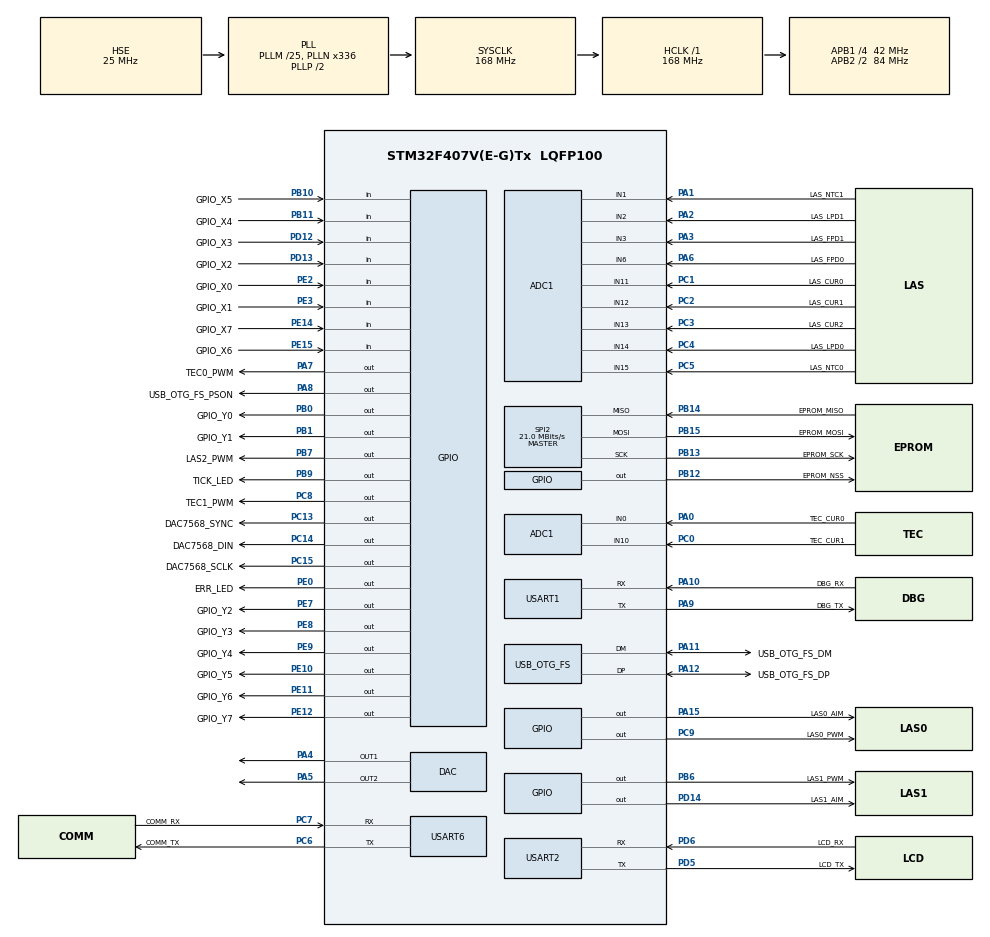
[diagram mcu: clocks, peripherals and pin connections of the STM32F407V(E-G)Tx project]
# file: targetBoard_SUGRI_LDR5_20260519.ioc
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ADC1.Channel-0\#ChannelRegularConversion=ADC_CHANNEL_0
ADC1.Channel-1\#ChannelRegularConversion=ADC_CHANNEL_1
ADC1.Channel-10\#ChannelRegularConversion=ADC_CHANNEL_15
ADC1.Channel-11\#ChannelRegularConversion=ADC_CHANNEL_TEMPSENSOR
ADC1.Channel-12\#ChannelRegularConversion=ADC_CHANNEL_VREFINT
ADC1.Channel-13\#ChannelRegularConversion=ADC_CHANNEL_VBAT
ADC1.Channel-2\#ChannelRegularConversion=ADC_CHANNEL_2
ADC1.Channel-3\#ChannelRegularConversion=ADC_CHANNEL_3
ADC1.Channel-4\#ChannelRegularConversion=ADC_CHANNEL_6
ADC1.Channel-5\#ChannelRegularConversion=ADC_CHANNEL_10
ADC1.Channel-6\#ChannelRegularConversion=ADC_CHANNEL_11
ADC1.Channel-7\#ChannelRegularConversion=ADC_CHANNEL_12
ADC1.Channel-8\#ChannelRegularConversion=ADC_CHANNEL_13
ADC1.Channel-9\#ChannelRegularConversion=ADC_CHANNEL_14
ADC1.ContinuousConvMode=ENABLE
ADC1.DMAContinuousRequests=DISABLE
ADC1.NbrOfConversion=14
ADC1.NbrOfConversionFlag=1
ADC1.Rank-0\#ChannelRegularConversion=1
ADC1.Rank-1\#ChannelRegularConversion=2
ADC1.Rank-10\#ChannelRegularConversion=11
ADC1.Rank-11\#ChannelRegularConversion=12
ADC1.Rank-12\#ChannelRegularConversion=13
ADC1.Rank-13\#ChannelRegularConversion=14
ADC1.Rank-2\#ChannelRegularConversion=3
ADC1.Rank-3\#ChannelRegularConversion=4
ADC1.Rank-4\#ChannelRegularConversion=5
ADC1.Rank-5\#ChannelRegularConversion=6
ADC1.Rank-6\#ChannelRegularConversion=7
ADC1.Rank-7\#ChannelRegularConversion=8
ADC1.Rank-8\#ChannelRegularConversion=9
ADC1.Rank-9\#ChannelRegularConversion=10
ADC1.SamplingTime-0\#ChannelRegularConversion=ADC_SAMPLETIME_144CYCLES
ADC1.SamplingTime-1\#ChannelRegularConversion=ADC_SAMPLETIME_144CYCLES
ADC1.SamplingTime-10\#ChannelRegularConversion=ADC_SAMPLETIME_144CYCLES
ADC1.SamplingTime-11\#ChannelRegularConversion=ADC_SAMPLETIME_144CYCLES
ADC1.SamplingTime-12\#ChannelRegularConversion=ADC_SAMPLETIME_144CYCLES
ADC1.SamplingTime-13\#ChannelRegularConversion=ADC_SAMPLETIME_144CYCLES
ADC1.SamplingTime-2\#ChannelRegularConversion=ADC_SAMPLETIME_144CYCLES
ADC1.SamplingTime-3\#ChannelRegularConversion=ADC_SAMPLETIME_144CYCLES
ADC1.SamplingTime-4\#ChannelRegularConversion=ADC_SAMPLETIME_144CYCLES
ADC1.SamplingTime-5\#ChannelRegularConversion=ADC_SAMPLETIME_144CYCLES
ADC1.SamplingTime-6\#ChannelRegularConversion=ADC_SAMPLETIME_144CYCLES
ADC1.SamplingTime-7\#ChannelRegularConversion=ADC_SAMPLETIME_144CYCLES
ADC1.SamplingTime-8\#ChannelRegularConversion=ADC_SAMPLETIME_144CYCLES
ADC1.SamplingTime-9\#ChannelRegularConversion=ADC_SAMPLETIME_144CYCLES
ADC1.ScanConvMode=ENABLE
ADC1.master=1
FATFS._CODE_PAGE=437
FATFS._FS_EXFAT=1
FATFS._FS_LOCK=255
FATFS._STRF_ENCODE=0
FATFS._USE_CHMOD=0
FATFS._USE_EXPAND=0
FATFS._USE_FASTSEEK=0
FATFS._USE_FIND=0
FATFS._USE_FORWARD=0
FATFS._USE_LABEL=0
FATFS._USE_LFN=3
FATFS._USE_MKFS=0
FATFS._USE_MUTEX=1
FATFS._USE_STRFUNC=0
Mcu.Family=STM32F4
Mcu.Name=STM32F407V(E-G)Tx
Mcu.Package=LQFP100
NVIC.OTG_FS_IRQn=true\:0\:0\:false\:false\:true\:false\:true\:true
NVIC.PriorityGroup=NVIC_PRIORITYGROUP_4
NVIC.TIM6_DAC_IRQn=true\:15\:0\:false\:false\:true\:false\:true\:true
NVIC.TimeBase=TIM6_DAC_IRQn
NVIC.TimeBaseIP=TIM6
PA0-WKUP.GPIO_Label=TEC_CUR0
PA0-WKUP.Signal=ADCx_IN0
PA1.GPIO_Label=LAS_NTC1
PA1.Signal=ADCx_IN1
PA10.GPIO_Label=DBG_RX
PA10.GPIO_PuPd=GPIO_PULLDOWN
PA10.GPIO_Speed=GPIO_SPEED_FREQ_MEDIUM
PA10.Mode=Asynchronous
PA10.Signal=USART1_RX
PA11.GPIO_Label=USB_OTG_FS_DM
PA11.Mode=Host_Only
PA11.Signal=USB_OTG_FS_DM
PA12.GPIO_Label=USB_OTG_FS_DP
PA12.Mode=Host_Only
PA12.Signal=USB_OTG_FS_DP
PA13.Mode=Trace_Asynchronous_SW
PA13.Signal=SYS_JTMS-SWDIO
PA14.Mode=Trace_Asynchronous_SW
PA14.Signal=SYS_JTCK-SWCLK
PA15.GPIO_Label=LAS0_AIM
PA15.GPIO_PuPd=GPIO_PULLDOWN
PA15.Signal=GPIO_Output
PA2.GPIO_Label=LAS_LPD1
PA2.Signal=ADCx_IN2
PA3.GPIO_Label=LAS_FPD1
PA3.Signal=ADCx_IN3
PA4.Signal=COMP_DAC1_group
PA5.Signal=COMP_DAC2_group
PA6.GPIO_Label=LAS_FPD0
PA6.Signal=ADCx_IN6
PA7.GPIO_Label=TEC0_PWM
PA7.GPIO_ModeDefaultOutputPP=GPIO_MODE_OUTPUT_PP
PA7.GPIO_PuPd=GPIO_PULLDOWN
PA7.Signal=GPIO_Output
PA8.GPIO_Label=USB_OTG_FS_PSON
PA8.GPIO_ModeDefaultOutputPP=GPIO_MODE_OUTPUT_PP
PA8.GPIO_PuPd=GPIO_PULLDOWN
PA8.Signal=GPIO_Output
PA9.GPIO_Label=DBG_TX
PA9.GPIO_PuPd=GPIO_PULLDOWN
PA9.GPIO_Speed=GPIO_SPEED_FREQ_MEDIUM
PA9.Mode=Asynchronous
PA9.Signal=USART1_TX
PB0.GPIO_Label=GPIO_Y0
PB0.GPIO_PuPd=GPIO_PULLDOWN
PB0.Signal=GPIO_Output
PB1.GPIO_Label=GPIO_Y1
PB1.GPIO_PuPd=GPIO_PULLDOWN
PB1.Signal=GPIO_Output
PB10.GPIO_Label=GPIO_X5
PB10.GPIO_PuPd=GPIO_PULLUP
PB10.Signal=GPIO_Input
PB11.GPIO_Label=GPIO_X4
PB11.GPIO_PuPd=GPIO_PULLUP
PB11.Signal=GPIO_Input
PB12.GPIO_Label=EPROM_NSS
PB12.Signal=GPIO_Output
PB13.GPIO_Label=EPROM_SCK
PB13.GPIO_PuPd=GPIO_PULLUP
PB13.Mode=Full_Duplex_Master
PB13.Signal=SPI2_SCK
PB14.GPIO_Label=EPROM_MISO
PB14.GPIO_PuPd=GPIO_PULLDOWN
PB14.Mode=Full_Duplex_Master
PB14.Signal=SPI2_MISO
PB15.GPIO_Label=EPROM_MOSI
PB15.GPIO_PuPd=GPIO_PULLDOWN
PB15.Mode=Full_Duplex_Master
PB15.Signal=SPI2_MOSI
PB3.Mode=Trace_Asynchronous_SW
PB3.Signal=SYS_JTDO-SWO
PB6.GPIO_Label=LAS1_PWM
PB6.GPIO_PuPd=GPIO_PULLDOWN
PB6.Signal=GPIO_Output
PB7.GPIO_Label=LAS2_PWM
PB7.GPIO_PuPd=GPIO_PULLDOWN
PB7.Signal=GPIO_Output
PB9.GPIO_Label=TICK_LED
PB9.Signal=GPIO_Output
PC0.GPIO_Label=TEC_CUR1
PC0.Signal=ADCx_IN10
PC1.GPIO_Label=LAS_CUR0
PC1.Signal=ADCx_IN11
PC13-ANTI_TAMP.GPIO_Label=DAC7568_SYNC
PC13-ANTI_TAMP.GPIO_PuPd=GPIO_PULLUP
PC13-ANTI_TAMP.Signal=GPIO_Output
PC14-OSC32_IN.GPIO_Label=DAC7568_DIN
PC14-OSC32_IN.Signal=GPIO_Output
PC15-OSC32_OUT.GPIO_Label=DAC7568_SCLK
PC15-OSC32_OUT.Signal=GPIO_Output
PC2.GPIO_Label=LAS_CUR1
PC2.Signal=ADCx_IN12
PC3.GPIO_Label=LAS_CUR2
PC3.Signal=ADCx_IN13
PC4.GPIO_Label=LAS_LPD0
PC4.Signal=ADCx_IN14
PC5.GPIO_Label=LAS_NTC0
PC5.Signal=ADCx_IN15
PC6.GPIO_Label=COMM_TX
PC6.Mode=Asynchronous
PC6.Signal=USART6_TX
PC7.GPIO_Label=COMM_RX
PC7.Mode=Asynchronous
PC7.Signal=USART6_RX
PC8.GPIO_Label=TEC1_PWM
PC8.GPIO_PuPd=GPIO_PULLDOWN
PC8.Signal=GPIO_Output
PC9.GPIO_Label=LAS0_PWM
PC9.GPIO_PuPd=GPIO_PULLDOWN
PC9.Signal=GPIO_Output
PD12.GPIO_Label=GPIO_X3
PD12.GPIO_PuPd=GPIO_PULLUP
PD12.Signal=GPIO_Input
PD13.GPIO_Label=GPIO_X2
PD13.GPIO_PuPd=GPIO_PULLUP
PD13.Signal=GPIO_Input
PD14.GPIO_Label=LAS1_AIM
PD14.GPIO_PuPd=GPIO_PULLDOWN
PD14.Signal=GPIO_Output
PD5.GPIO_Label=LCD_TX
PD5.Mode=Asynchronous
PD5.Signal=USART2_TX
PD6.GPIO_Label=LCD_RX
PD6.Mode=Asynchronous
PD6.Signal=USART2_RX
PE0.GPIO_Label=ERR_LED
PE0.GPIO_PuPd=GPIO_NOPULL
PE0.Signal=GPIO_Output
PE10.GPIO_Label=GPIO_Y5
PE10.GPIO_PuPd=GPIO_PULLDOWN
PE10.Signal=GPIO_Output
PE11.GPIO_Label=GPIO_Y6
PE11.GPIO_PuPd=GPIO_PULLDOWN
PE11.Signal=GPIO_Output
PE12.GPIO_Label=GPIO_Y7
PE12.GPIO_PuPd=GPIO_PULLDOWN
PE12.Signal=GPIO_Output
PE14.GPIO_Label=GPIO_X7
PE14.GPIO_PuPd=GPIO_PULLUP
PE14.Signal=GPIO_Input
PE15.GPIO_Label=GPIO_X6
PE15.GPIO_PuPd=GPIO_PULLUP
PE15.Signal=GPIO_Input
PE2.GPIO_Label=GPIO_X0
PE2.GPIO_PuPd=GPIO_PULLUP
PE2.Signal=GPIO_Input
PE3.GPIO_Label=GPIO_X1
PE3.GPIO_PuPd=GPIO_PULLUP
PE3.Signal=GPIO_Input
PE7.GPIO_Label=GPIO_Y2
PE7.GPIO_PuPd=GPIO_PULLDOWN
PE7.Signal=GPIO_Output
PE8.GPIO_Label=GPIO_Y3
PE8.GPIO_PuPd=GPIO_PULLDOWN
PE8.Signal=GPIO_Output
PE9.GPIO_Label=GPIO_Y4
PE9.GPIO_PuPd=GPIO_PULLDOWN
PE9.Signal=GPIO_Output
PH0-OSC_IN.Mode=HSE-External-Oscillator
PH0-OSC_IN.Signal=RCC_OSC_IN
PH1-OSC_OUT.Mode=HSE-External-Oscillator
PH1-OSC_OUT.Signal=RCC_OSC_OUT
ProjectManager.HeapSize=0x2000
ProjectManager.StackSize=0x1000
ProjectManager.TargetToolchain=MDK-ARM V5.32
RCC.48MHZClocksFreq_Value=48000000
RCC.AHBFreq_Value=168000000
RCC.APB1CLKDivider=RCC_HCLK_DIV4
RCC.APB1Freq_Value=42000000
RCC.APB1TimFreq_Value=84000000
RCC.APB2CLKDivider=RCC_HCLK_DIV2
RCC.APB2Freq_Value=84000000
RCC.APB2TimFreq_Value=168000000
RCC.CortexFreq_Value=168000000
RCC.HCLKFreq_Value=168000000
RCC.HSE_VALUE=25000000
RCC.HSI_VALUE=16000000
RCC.LSE_VALUE=32768
RCC.PLLM=25
RCC.PLLN=336
RCC.PLLQ=7
RCC.PWR_Regulator_Voltage_Scale=PWR_REGULATOR_VOLTAGE_SCALE1
RCC.RCC_RTC_Clock_Source=RCC_RTCCLKSOURCE_LSE
RCC.RCC_RTC_Clock_SourceVirtual=RCC_RTCCLKSOURCE_LSE
RCC.SYSCLKFreq_VALUE=168000000
RCC.SYSCLKSource=RCC_SYSCLKSOURCE_PLLCLK
RCC.VCOOutputFreq_Value=336000000
SH.ADCx_IN0.0=ADC1_IN0,IN0
SH.ADCx_IN1.0=ADC1_IN1,IN1
SH.ADCx_IN10.0=ADC1_IN10,IN10
SH.ADCx_IN11.0=ADC1_IN11,IN11
SH.ADCx_IN12.0=ADC1_IN12,IN12
SH.ADCx_IN13.0=ADC1_IN13,IN13
SH.ADCx_IN14.0=ADC1_IN14,IN14
SH.ADCx_IN15.0=ADC1_IN15,IN15
SH.ADCx_IN2.0=ADC1_IN2,IN2
SH.ADCx_IN3.0=ADC1_IN3,IN3
SH.ADCx_IN6.0=ADC1_IN6,IN6
SH.COMP_DAC1_group.0=DAC_OUT1,DAC_OUT1
SH.COMP_DAC2_group.0=DAC_OUT2,DAC_OUT2
SPI2.CalculateBaudRate=21.0 MBits/s
SPI2.Direction=SPI_DIRECTION_2LINES
SPI2.Mode=SPI_MODE_MASTER
SPI2.VirtualType=VM_MASTER
USART1.VirtualMode=VM_ASYNC
USART2.VirtualMode=VM_ASYNC
USART6.VirtualMode=VM_ASYNC
USB_HOST.BSP.number=1
USB_HOST.USBH_DEBUG_LEVEL-MSC_FS=0
USB_HOST.USBH_HandleTypeDef-MSC_FS=hUsbHostFS
USB_HOST.VirtualModeFS=Msc
USB_HOST0.BSP.STBoard=false
USB_HOST0.BSP.api=Unknown
USB_HOST0.BSP.condition=SW_VBUS_DRIVE_MSC_FS \= false
USB_HOST0.BSP.instance=PA8
USB_HOST0.BSP.ip=GPIO
USB_HOST0.BSP.mode=Output
USB_HOST0.BSP.name=Drive_VBUS_FS
USB_HOST0.BSP.solution=PA8
USB_OTG_FS.VirtualMode=Host_Only
USB_OTG_FS.phy_itface=HCD_PHY_EMBEDDED
VP_ADC1_TempSens_Input.Mode=IN-TempSens
VP_ADC1_Vbat_Input.Mode=IN-Vbat
VP_ADC1_Vref_Input.Mode=IN-Vrefint
VP_CRC_VS_CRC.Mode=CRC_Activate
VP_FATFS_VS_USB.Mode=USB
VP_RNG_VS_RNG.Mode=RNG_Activate
VP_SYS_VS_tim6.Mode=TIM6
VP_USB_HOST_VS_USB_HOST_MSC_FS.Mode=MSC_FS
board=custom

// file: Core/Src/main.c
/*----------------------------------------------------------------------------
 * 文件编码约定: 本文件为 UTF-8 编码(带BOM)。
 * 本工程源码统一使用 UTF-8(带BOM) 保存: 新建或修改任何源文件时,
 * 请以 UTF-8 编码保存, 并在文件头保留本注释。
 *----------------------------------------------------------------------------*/
/* USER CODE BEGIN Header */
/**
  ******************************************************************************
  * @file           : main.c
  * @brief          : Main program body
  ******************************************************************************
  * @attention
  *
  * Copyright (c) 2026 STMicroelectronics.
  * All rights reserved.
  *
  * This software is licensed under terms that can be found in the LICENSE file
  * in the root directory of this software component.
  * If no LICENSE file comes with this software, it is provided AS-IS.
  *
  ******************************************************************************
  */
/* USER CODE END Header */
#include "main.h"
#include "adc.h"
#include "crc.h"
#include "dac.h"
#include "fatfs.h"
#include "rng.h"
#include "spi.h"
#include "usart.h"
#include "usb_host.h"
#include "gpio.h"

/* USER CODE BEGIN Includes */
#include "bootloader.h"
/* USER CODE END Includes */

void SystemClock_Config(void);
void MX_USB_HOST_Process(void);

int main(void)
{

  /* MCU Configuration--------------------------------------------------------*/

  /* Reset of all peripherals, Initializes the Flash interface and the Systick. */
  HAL_Init();

  /* Configure the system clock */
  SystemClock_Config();

  /* Initialize all configured peripherals */
  MX_GPIO_Init();
  MX_DAC_Init();
  MX_ADC1_Init();
  MX_SPI2_Init();
  MX_USART1_UART_Init();
  MX_USART6_UART_Init();
  MX_CRC_Init();
  MX_RNG_Init();
  MX_FATFS_Init();
  MX_USB_HOST_Init();
  MX_USART2_UART_Init();
  /* USER CODE BEGIN 2 */
	bootLoadInit();
	HAL_FLASH_Unlock();
  /* USER CODE END 2 */

  /* Infinite loop */
  while (1)
  {
    MX_USB_HOST_Process();

    /* USER CODE BEGIN 3 */
		bootLoadProcess();
  }
  /* USER CODE END 3 */
}

void SystemClock_Config(void)
{
  RCC_OscInitTypeDef RCC_OscInitStruct = {0};
  RCC_ClkInitTypeDef RCC_ClkInitStruct = {0};

  /** Configure the main internal regulator output voltage
  */
  __HAL_RCC_PWR_CLK_ENABLE();
  __HAL_PWR_VOLTAGESCALING_CONFIG(PWR_REGULATOR_VOLTAGE_SCALE1);

  /** Initializes the RCC Oscillators according to the specified parameters
  * in the RCC_OscInitTypeDef structure.
  */
  RCC_OscInitStruct.OscillatorType = RCC_OSCILLATORTYPE_HSE;
  RCC_OscInitStruct.HSEState = RCC_HSE_ON;
  RCC_OscInitStruct.PLL.PLLState = RCC_PLL_ON;
  RCC_OscInitStruct.PLL.PLLSource = RCC_PLLSOURCE_HSE;
  RCC_OscInitStruct.PLL.PLLM = 25;
  RCC_OscInitStruct.PLL.PLLN = 336;
  RCC_OscInitStruct.PLL.PLLP = RCC_PLLP_DIV2;
  RCC_OscInitStruct.PLL.PLLQ = 7;
  if (HAL_RCC_OscConfig(&RCC_OscInitStruct) != HAL_OK)
  {
    Error_Handler();
  }

  /** Initializes the CPU, AHB and APB buses clocks
  */
  RCC_ClkInitStruct.ClockType = RCC_CLOCKTYPE_HCLK|RCC_CLOCKTYPE_SYSCLK
                              |RCC_CLOCKTYPE_PCLK1|RCC_CLOCKTYPE_PCLK2;
  RCC_ClkInitStruct.SYSCLKSource = RCC_SYSCLKSOURCE_PLLCLK;
  RCC_ClkInitStruct.AHBCLKDivider = RCC_SYSCLK_DIV1;
  RCC_ClkInitStruct.APB1CLKDivider = RCC_HCLK_DIV4;
  RCC_ClkInitStruct.APB2CLKDivider = RCC_HCLK_DIV2;

  if (HAL_RCC_ClockConfig(&RCC_ClkInitStruct, FLASH_LATENCY_5) != HAL_OK)
  {
    Error_Handler();
  }
}

void HAL_TIM_PeriodElapsedCallback(TIM_HandleTypeDef *htim)
{
  if (htim->Instance == TIM6)
  {
    HAL_IncTick();
  }
}

void Error_Handler(void)
{
  __disable_irq();
  while (1)
  {
  }
}
